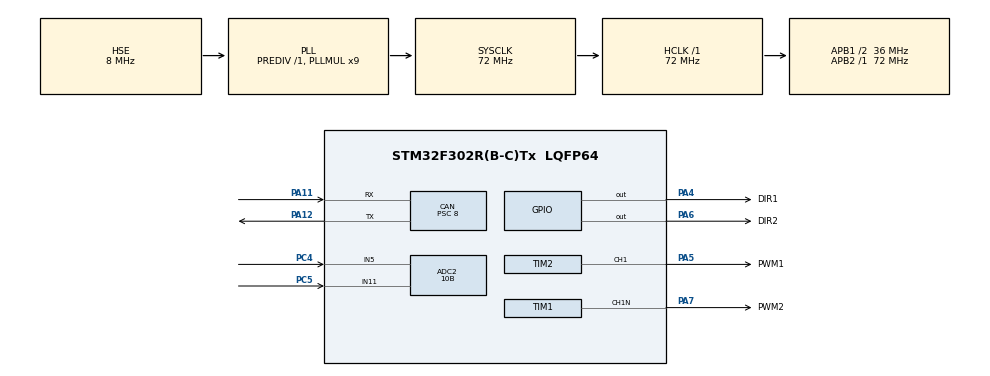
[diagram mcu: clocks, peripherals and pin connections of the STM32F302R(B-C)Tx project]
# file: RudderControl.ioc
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ADC2.Channel-0\#ChannelRegularConversion=ADC_CHANNEL_5
ADC2.Channel-1\#ChannelRegularConversion=ADC_CHANNEL_11
ADC2.ContinuousConvMode=ENABLE
ADC2.DMAContinuousRequests=ENABLE
ADC2.EOCSelection=ADC_EOC_SEQ_CONV
ADC2.NbrOfConversion=2
ADC2.NbrOfConversionFlag=1
ADC2.Offset-0\#ChannelRegularConversion=0
ADC2.Offset-1\#ChannelRegularConversion=0
ADC2.OffsetNumber-0\#ChannelRegularConversion=ADC_OFFSET_NONE
ADC2.OffsetNumber-1\#ChannelRegularConversion=ADC_OFFSET_NONE
ADC2.Rank-0\#ChannelRegularConversion=1
ADC2.Rank-1\#ChannelRegularConversion=2
ADC2.Resolution=ADC_RESOLUTION_10B
ADC2.SamplingTime-0\#ChannelRegularConversion=ADC_SAMPLETIME_181CYCLES_5
ADC2.SamplingTime-1\#ChannelRegularConversion=ADC_SAMPLETIME_181CYCLES_5
ADC2.SamplingTimeOPAMP-1\#ChannelRegularConversion=ADC_SAMPLETIME_61CYCLES_5
CAN.ABOM=ENABLE
CAN.BS1=CAN_BS1_15TQ
CAN.BS2=CAN_BS2_2TQ
CAN.CalculateBaudRate=250000
CAN.CalculateTimeBit=4000
CAN.CalculateTimeQuantum=222.22222222222223
CAN.Mode=CAN_MODE_SILENT_LOOPBACK
CAN.NART=ENABLE
CAN.Prescaler=8
CAN.TXFP=ENABLE
Dma.ADC2.0.Direction=DMA_PERIPH_TO_MEMORY
Dma.ADC2.0.Instance=DMA2_Channel1
Dma.ADC2.0.MemDataAlignment=DMA_MDATAALIGN_HALFWORD
Dma.ADC2.0.MemInc=DMA_MINC_ENABLE
Dma.ADC2.0.Mode=DMA_CIRCULAR
Dma.ADC2.0.PeriphDataAlignment=DMA_PDATAALIGN_HALFWORD
Dma.ADC2.0.PeriphInc=DMA_PINC_DISABLE
Dma.ADC2.0.Priority=DMA_PRIORITY_LOW
Dma.Request0=ADC2
Mcu.Family=STM32F3
Mcu.Name=STM32F302R(B-C)Tx
Mcu.Package=LQFP64
NVIC.ADC1_2_IRQn=true\:0\:0\:false\:false\:true\:true\:true\:true
NVIC.CAN_RX1_IRQn=true\:0\:0\:false\:false\:true\:true\:true\:true
NVIC.CAN_SCE_IRQn=true\:0\:0\:false\:false\:true\:true\:true\:true
NVIC.DMA2_Channel1_IRQn=true\:0\:0\:false\:false\:true\:false\:true\:true
NVIC.PriorityGroup=NVIC_PRIORITYGROUP_4
PA11.Mode=CAN_Activate
PA11.Signal=CAN_RX
PA12.Mode=CAN_Activate
PA12.Signal=CAN_TX
PA13.Mode=Serial_Wire
PA13.Signal=SYS_JTMS-SWDIO
PA14.Mode=Serial_Wire
PA14.Signal=SYS_JTCK-SWCLK
PA4.GPIO_Label=DIR1
PA4.Signal=GPIO_Output
PA5.GPIO_Label=PWM1
PA5.Signal=S_TIM2_CH1_ETR
PA6.GPIO_Label=DIR2
PA6.Signal=GPIO_Output
PA7.GPIO_Label=PWM2
PA7.Mode=PWM Generation1 CH1N
PA7.Signal=TIM1_CH1N
PC4.Mode=IN5-Single-Ended
PC4.Signal=ADC2_IN5
PC5.Mode=IN11-Single-Ended
PC5.Signal=ADC2_IN11
PF0-OSC_IN.GPIO_Label=XTAL1
PF0-OSC_IN.Mode=HSE-External-Oscillator
PF0-OSC_IN.Signal=RCC_OSC_IN
PF1-OSC_OUT.GPIO_Label=XTAL2
PF1-OSC_OUT.Mode=HSE-External-Oscillator
PF1-OSC_OUT.Signal=RCC_OSC_OUT
ProjectManager.HeapSize=0x200
ProjectManager.StackSize=0x400
ProjectManager.TargetToolchain=STM32CubeIDE
RCC.AHBFreq_Value=72000000
RCC.APB1CLKDivider=RCC_HCLK_DIV2
RCC.APB1Freq_Value=36000000
RCC.APB1TimFreq_Value=72000000
RCC.APB2Freq_Value=72000000
RCC.APB2TimFreq_Value=72000000
RCC.CortexFreq_Value=72000000
RCC.HCLKFreq_Value=72000000
RCC.HSE_VALUE=8000000
RCC.HSI_VALUE=8000000
RCC.LSE_VALUE=32768
RCC.PLLM=4
RCC.PLLMUL=RCC_PLL_MUL9
RCC.PLLN=72
RCC.PLLSourceVirtual=RCC_PLLSOURCE_HSE
RCC.SYSCLKFreq_VALUE=72000000
RCC.SYSCLKSourceVirtual=RCC_SYSCLKSOURCE_PLLCLK
RCC.USBFreq_Value=72000000
RCC.VCOOutputFreq_Value=144000000
SH.S_TIM2_CH1_ETR.0=TIM2_CH1,PWM Generation1 CH1
TIM1.Channel-PWM\ Generation1\ CH1N=TIM_CHANNEL_1
TIM1.Period=1023
TIM1.Prescaler=4
TIM1.Pulse-PWM\ Generation1\ CH1N=128
TIM2.Channel-PWM\ Generation1\ CH1=TIM_CHANNEL_1
TIM2.Period=1023
TIM2.Prescaler=4
TIM2.Pulse-PWM\ Generation1\ CH1=128
VP_TIM1_VS_ClockSourceINT.Mode=Internal
VP_TIM2_VS_ClockSourceINT.Mode=Internal
board=custom

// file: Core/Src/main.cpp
/* USER CODE BEGIN Header */
/**
  ******************************************************************************
  * @file           : main.c
  * @brief          : Main program body
  ******************************************************************************
  * @attention
  *
  * Copyright (c) 2025 STMicroelectronics.
  * All rights reserved.
  *
  * This software is licensed under terms that can be found in the LICENSE file
  * in the root directory of this software component.
  * If no LICENSE file comes with this software, it is provided AS-IS.
  *
  ******************************************************************************
  */
/* USER CODE END Header */
#include "main.h"
#include "adc.h"
#include "can.h"
#include "dma.h"
#include "tim.h"
#include "gpio.h"
#include "motor.h"
#include "pid.h"
#include "stm32f3xx_hal_adc.h"
#include "stm32f3xx_hal.h"

/* USER CODE BEGIN PV */
  uint8_t adc_ready = 0;
  uint16_t CanMessage[2] = {0};
  Motor motor_left(GPIOA, GPIO_PIN_4, // DIR pin
		  &(TIM2->CCR1), 			  // PWM output
		  &adc_value[0], 740, 240,    // Pot input, max, min
		  &CanMessage[0], 			      // Set Point
		  5.0, 0.0, 0.0);			  // PID

  Motor motor_right(GPIOA, GPIO_PIN_6, // DIR pin
  		  &(TIM1->CCR1), 			  // PWM output
  		  &adc_value[1], 740, 240,    // Pot input, max, min
  		  &CanMessage[0], 			      // Set Point
  		  5.0, 0.0, 0.0);			  // PID
/* USER CODE END PV */

void SystemClock_Config(void);

int main(void)
{

  /* MCU Configuration--------------------------------------------------------*/

  /* Reset of all peripherals, Initializes the Flash interface and the Systick. */
  HAL_Init();

  /* Configure the system clock */
  SystemClock_Config();

  /* Initialize all configured peripherals */
  MX_GPIO_Init();
  MX_DMA_Init();
  MX_CAN_Init();
  MX_TIM1_Init();
  MX_TIM2_Init();
  MX_ADC2_Init();

  /* Infinite loop */
  while (1)
  {

	 // motor_left.controlLoop();
	  //motor_right.controlLoop();
  }
}

void SystemClock_Config(void)
{
  RCC_OscInitTypeDef RCC_OscInitStruct = {0};
  RCC_ClkInitTypeDef RCC_ClkInitStruct = {0};
  RCC_PeriphCLKInitTypeDef PeriphClkInit = {0};

  /** Initializes the RCC Oscillators according to the specified parameters
  * in the RCC_OscInitTypeDef structure.
  */
  RCC_OscInitStruct.OscillatorType = RCC_OSCILLATORTYPE_HSE;
  RCC_OscInitStruct.HSEState = RCC_HSE_ON;
  RCC_OscInitStruct.HSEPredivValue = RCC_HSE_PREDIV_DIV1;
  RCC_OscInitStruct.HSIState = RCC_HSI_ON;
  RCC_OscInitStruct.PLL.PLLState = RCC_PLL_ON;
  RCC_OscInitStruct.PLL.PLLSource = RCC_PLLSOURCE_HSE;
  RCC_OscInitStruct.PLL.PLLMUL = RCC_PLL_MUL9;
  if (HAL_RCC_OscConfig(&RCC_OscInitStruct) != HAL_OK)
  {
    Error_Handler();
  }

  /** Initializes the CPU, AHB and APB buses clocks
  */
  RCC_ClkInitStruct.ClockType = RCC_CLOCKTYPE_HCLK|RCC_CLOCKTYPE_SYSCLK
                              |RCC_CLOCKTYPE_PCLK1|RCC_CLOCKTYPE_PCLK2;
  RCC_ClkInitStruct.SYSCLKSource = RCC_SYSCLKSOURCE_PLLCLK;
  RCC_ClkInitStruct.AHBCLKDivider = RCC_SYSCLK_DIV1;
  RCC_ClkInitStruct.APB1CLKDivider = RCC_HCLK_DIV2;
  RCC_ClkInitStruct.APB2CLKDivider = RCC_HCLK_DIV1;

  if (HAL_RCC_ClockConfig(&RCC_ClkInitStruct, FLASH_LATENCY_2) != HAL_OK)
  {
    Error_Handler();
  }
  PeriphClkInit.PeriphClockSelection = RCC_PERIPHCLK_TIM1|RCC_PERIPHCLK_ADC12;
  PeriphClkInit.Adc12ClockSelection = RCC_ADC12PLLCLK_DIV1;
  PeriphClkInit.Tim1ClockSelection = RCC_TIM1CLK_HCLK;
  if (HAL_RCCEx_PeriphCLKConfig(&PeriphClkInit) != HAL_OK)
  {
    Error_Handler();
  }
}

void Error_Handler(void)
{
  __disable_irq();
  while (1)
  {
  }
}
